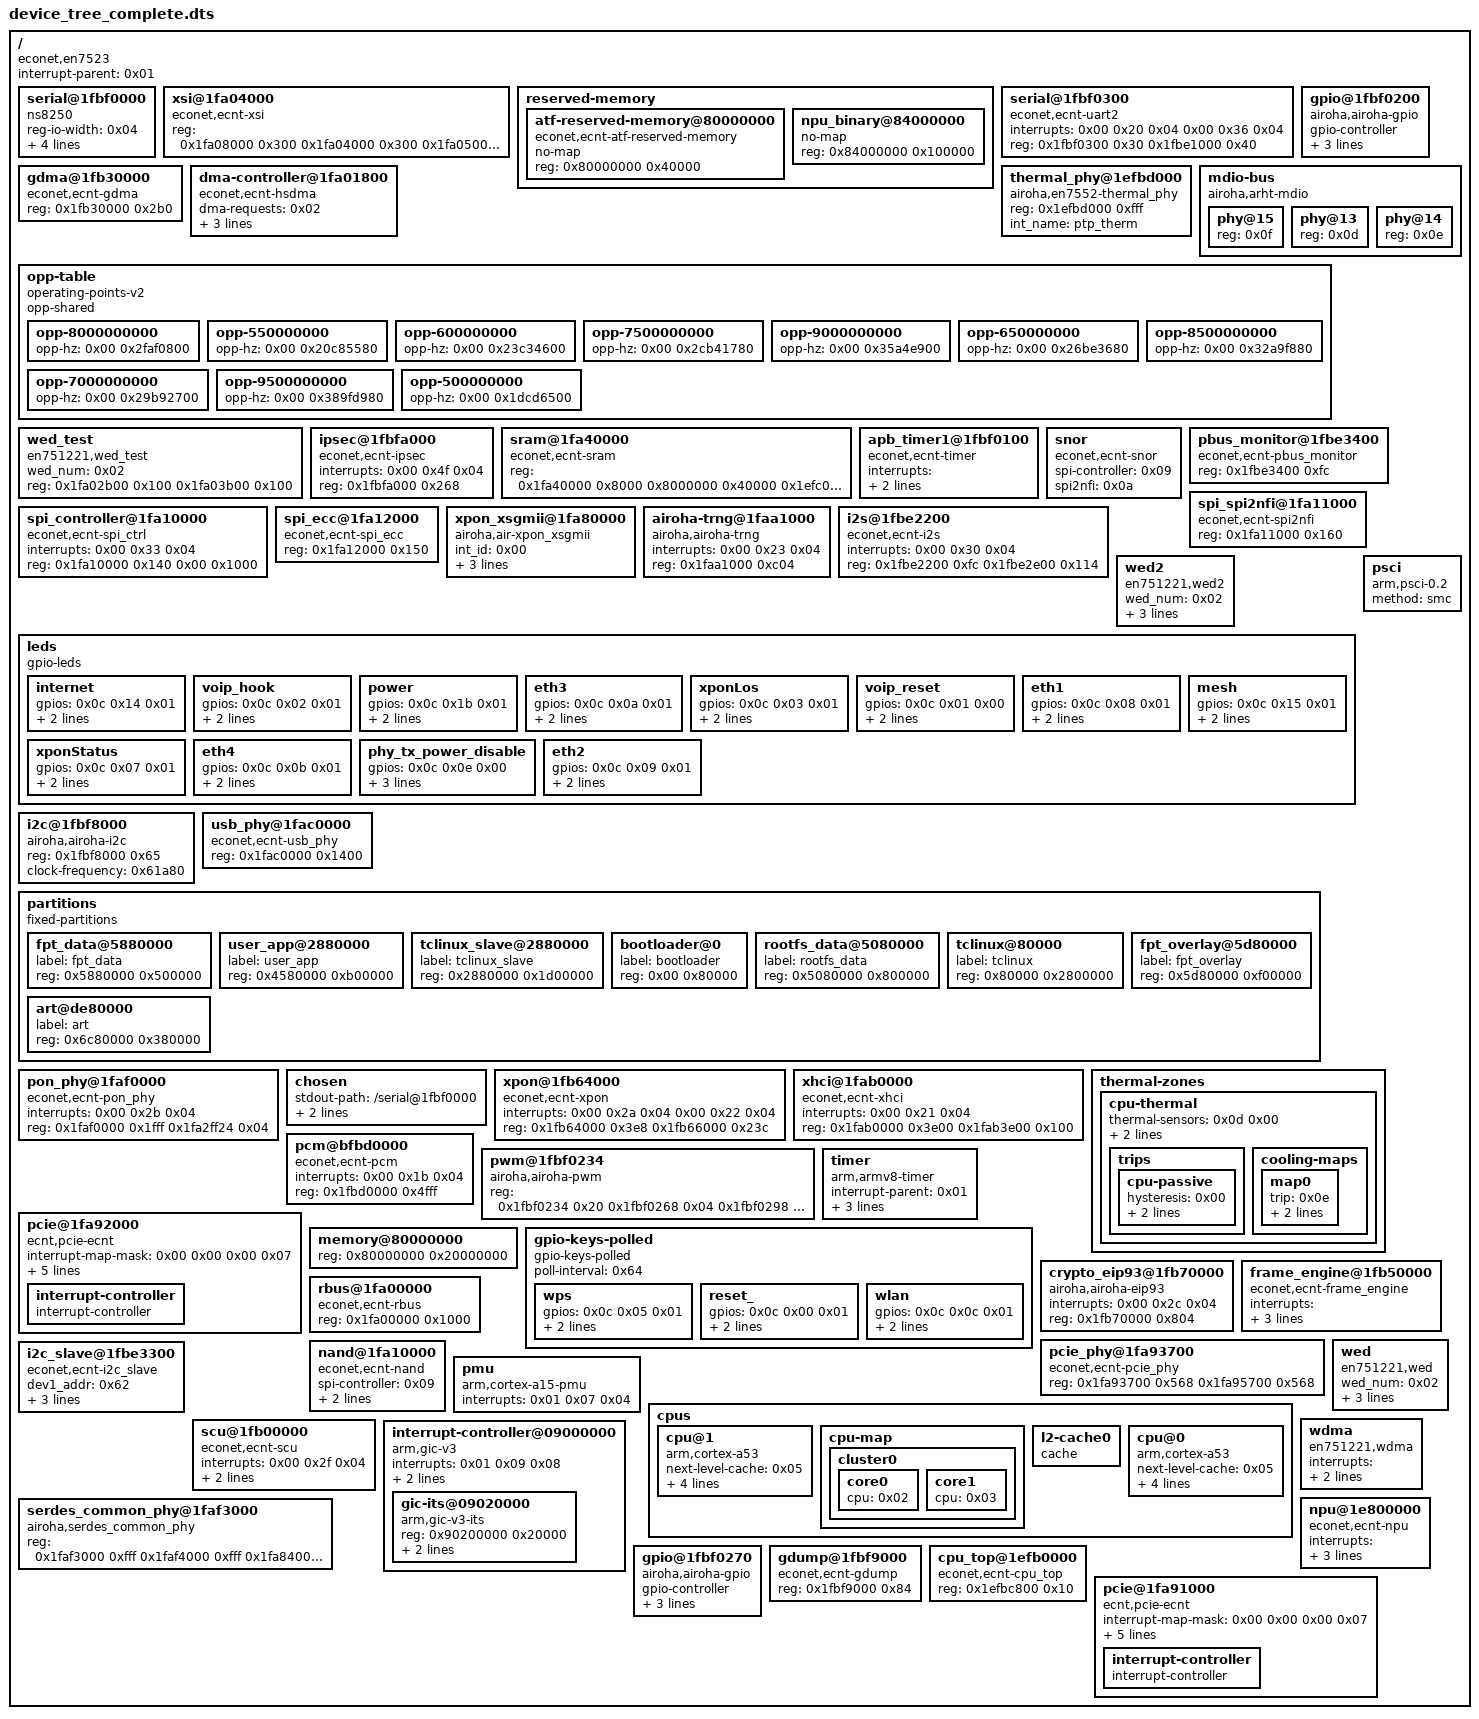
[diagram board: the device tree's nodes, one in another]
/dts-v1/;

/ {
	compatible = "econet,en7523\0airoha,en7523";
	interrupt-parent = <0x01>;
	#address-cells = <0x01>;
	#size-cells = <0x01>;

	serial@1fbf0000 {
		reg-io-width = <0x04>;
		compatible = "ns8250";
		status = "okay";
		interrupts = <0x00 0x12 0x04>;
		reg = <0x1fbf0000 0x30>;
		clock-frequency = <0x1c2000>;
		reg-shift = <0x02>;
	};

	xsi@1fa04000 {
		compatible = "econet,ecnt-xsi";
		reg = <0x1fa08000 0x300 0x1fa04000 0x300 0x1fa05000 0x300 0x1fa07000 0x300 0x1fa09000 0x300>;
	};

	reserved-memory {
		ranges;
		#address-cells = <0x01>;
		#size-cells = <0x01>;

		atf-reserved-memory@80000000 {
			compatible = "econet,ecnt-atf-reserved-memory";
			no-map;
			reg = <0x80000000 0x40000>;
		};

		npu_binary@84000000 {
			no-map;
			phandle = <0x06>;
			reg = <0x84000000 0x100000>;
		};
	};

	serial@1fbf0300 {
		compatible = "econet,ecnt-uart2";
		interrupts = <0x00 0x20 0x04 0x00 0x36 0x04>;
		reg = <0x1fbf0300 0x30 0x1fbe1000 0x40>;
	};

	gdma@1fb30000 {
		compatible = "econet,ecnt-gdma";
		reg = <0x1fb30000 0x2b0>;
	};

	dma-controller@1fa01800 {
		#dma-cells = <0x01>;
		compatible = "econet,ecnt-hsdma";
		dma-requests = <0x02>;
		dma-channels = <0x02>;
		interrupts = <0x00 0x3f 0x04>;
		reg = <0x1fa01800 0x300>;
	};

	thermal_phy@1efbd000 {
		compatible = "airoha,en7552-thermal_phy";
		#thermal-sensor-cells = <0x00>;
		phandle = <0x0d>;
		reg = <0x1efbd000 0xfff>;
		int_name = "ptp_therm";
	};

	gpio@1fbf0200 {
		compatible = "airoha,airoha-gpio";
		gpio-controller;
		phandle = <0x0c>;
		reg = <0x1fbf0204 0x04 0x1fbf0200 0x04 0x1fbf0220 0x04 0x1fbf0214 0x04>;
		#gpio-cells = <0x02>;
		gpio_base = <0x00>;
	};

	mdio-bus {
		compatible = "airoha,arht-mdio";

		phy@15 {
			reg = <0x0f>;
		};

		phy@13 {
			reg = <0x0d>;
		};

		phy@14 {
			reg = <0x0e>;
		};
	};

	opp-table {
		compatible = "operating-points-v2";
		phandle = <0x04>;
		opp-shared;

		opp-8000000000 {
			opp-hz = <0x00 0x2faf0800>;
		};

		opp-550000000 {
			opp-hz = <0x00 0x20c85580>;
		};

		opp-600000000 {
			opp-hz = <0x00 0x23c34600>;
		};

		opp-7500000000 {
			opp-hz = <0x00 0x2cb41780>;
		};

		opp-9000000000 {
			opp-hz = <0x00 0x35a4e900>;
		};

		opp-650000000 {
			opp-hz = <0x00 0x26be3680>;
		};

		opp-8500000000 {
			opp-hz = <0x00 0x32a9f880>;
		};

		opp-7000000000 {
			opp-hz = <0x00 0x29b92700>;
		};

		opp-9500000000 {
			opp-hz = <0x00 0x389fd980>;
		};

		opp-500000000 {
			opp-hz = <0x00 0x1dcd6500>;
		};
	};

	wed_test {
		compatible = "en751221,wed_test";
		wed_num = <0x02>;
		reg = <0x1fa02b00 0x100 0x1fa03b00 0x100>;
	};

	ipsec@1fbfa000 {
		compatible = "econet,ecnt-ipsec";
		interrupts = <0x00 0x4f 0x04>;
		reg = <0x1fbfa000 0x268>;
	};

	sram@1fa40000 {
		compatible = "econet,ecnt-sram";
		reg = <0x1fa40000 0x8000 0x8000000 0x40000 0x1efc0000 0x40000 0x1e880000 0x40000 0x1fbe3000 0x200>;
	};

	apb_timer1@1fbf0100 {
		compatible = "econet,ecnt-timer";
		interrupts = <0x00 0x14 0x04 0x00 0x15 0x04 0x00 0x16 0x04 0x00 0x19 0x04>;
		reg = <0x1fbf0100 0x40>;
	};

	snor {
		compatible = "econet,ecnt-snor";
		spi-controller = <0x09>;
		spi2nfi = <0x0a>;
	};

	pbus_monitor@1fbe3400 {
		compatible = "econet,ecnt-pbus_monitor";
		reg = <0x1fbe3400 0xfc>;
	};

	spi_spi2nfi@1fa11000 {
		compatible = "econet,ecnt-spi2nfi";
		phandle = <0x0a>;
		reg = <0x1fa11000 0x160>;
	};

	spi_controller@1fa10000 {
		compatible = "econet,ecnt-spi_ctrl";
		interrupts = <0x00 0x33 0x04>;
		phandle = <0x09>;
		reg = <0x1fa10000 0x140 0x00 0x1000>;
	};

	spi_ecc@1fa12000 {
		compatible = "econet,ecnt-spi_ecc";
		phandle = <0x0b>;
		reg = <0x1fa12000 0x150>;
	};

	xpon_xsgmii@1fa80000 {
		int_id = <0x00>;
		compatible = "airoha,air-xpon_xsgmii";
		reg = <0x1fa80a00 0x168 0x1fa80000 0x64 0x1fa86000 0x3ff>;
		int_name = "xpon_xsgmii";
	};

	airoha-trng@1faa1000 {
		compatible = "airoha,airoha-trng";
		interrupts = <0x00 0x23 0x04>;
		reg = <0x1faa1000 0xc04>;
	};

	i2s@1fbe2200 {
		compatible = "econet,ecnt-i2s";
		interrupts = <0x00 0x30 0x04>;
		reg = <0x1fbe2200 0xfc 0x1fbe2e00 0x114>;
	};

	wed2 {
		compatible = "en751221,wed2";
		wed_num = <0x02>;
		interrupts = <0x00 0x43 0x04 0x00 0x44 0x04>;
		reg = <0x1fa02000 0xb00 0x1fa03000 0xb00>;
		pci_slot_map = <0x00 0x01>;
	};

	leds {
		compatible = "gpio-leds";

		internet {
			gpios = <0x0c 0x14 0x01>;
			label = "internet";
			linux,default-trigger = "timer";
		};

		voip_hook {
			gpios = <0x0c 0x02 0x01>;
			label = "voip_hook";
			linux,default-trigger = "timer";
		};

		power {
			gpios = <0x0c 0x1b 0x01>;
			label = "power";
			linux,default-trigger = "timer";
		};

		eth3 {
			gpios = <0x0c 0x0a 0x01>;
			label = "eth3";
			linux,default-trigger = "none";
		};

		xponLos {
			gpios = <0x0c 0x03 0x01>;
			label = "xponLos";
			linux,default-trigger = "timer";
		};

		voip_reset {
			gpios = <0x0c 0x01 0x00>;
			label = "voip_reset";
			linux,default-trigger = "none";
		};

		eth1 {
			gpios = <0x0c 0x08 0x01>;
			label = "eth1";
			linux,default-trigger = "none";
		};

		mesh {
			gpios = <0x0c 0x15 0x01>;
			label = "mesh";
			linux,default-trigger = "timer";
		};

		xponStatus {
			gpios = <0x0c 0x07 0x01>;
			label = "xponStatus";
			linux,default-trigger = "timer";
		};

		eth4 {
			gpios = <0x0c 0x0b 0x01>;
			label = "eth4";
			linux,default-trigger = "none";
		};

		phy_tx_power_disable {
			gpios = <0x0c 0x0e 0x00>;
			label = "phy_tx_power_disable";
			default-state = "on";
			linux,default-trigger = "dsldev";
		};

		eth2 {
			gpios = <0x0c 0x09 0x01>;
			label = "eth2";
			linux,default-trigger = "none";
		};
	};

	i2c@1fbf8000 {
		compatible = "airoha,airoha-i2c";
		reg = <0x1fbf8000 0x65>;
		clock-frequency = <0x61a80>;
	};

	psci {
		compatible = "arm,psci-0.2";
		method = "smc";
	};

	usb_phy@1fac0000 {
		compatible = "econet,ecnt-usb_phy";
		reg = <0x1fac0000 0x1400>;
	};

	partitions {
		compatible = "fixed-partitions";
		#address-cells = <0x01>;
		#size-cells = <0x01>;

		fpt_data@5880000 {
			label = "fpt_data";
			reg = <0x5880000 0x500000>;
		};

		user_app@2880000 {
			label = "user_app";
			reg = <0x4580000 0xb00000>;
		};

		tclinux_slave@2880000 {
			label = "tclinux_slave";
			reg = <0x2880000 0x1d00000>;
		};

		bootloader@0 {
			label = "bootloader";
			reg = <0x00 0x80000>;
		};

		rootfs_data@5080000 {
			label = "rootfs_data";
			reg = <0x5080000 0x800000>;
		};

		tclinux@80000 {
			label = "tclinux";
			reg = <0x80000 0x2800000>;
		};

		fpt_overlay@5d80000 {
			label = "fpt_overlay";
			reg = <0x5d80000 0xf00000>;
		};

		art@de80000 {
			label = "art";
			reg = <0x6c80000 0x380000>;
		};
	};

	pon_phy@1faf0000 {
		compatible = "econet,ecnt-pon_phy";
		interrupts = <0x00 0x2b 0x04>;
		reg = <0x1faf0000 0x1fff 0x1fa2ff24 0x04>;
	};

	chosen {
		stdout-path = "/serial@1fbf0000";
		bootargs = "sdram_conf=0x00108893 vendor_name=ECONET Technologies Corp. product_name=xPON ONU ethaddr=20:be:b4:20:b9:b6 snmp_sysobjid=1.2.3.4.5 country_code=ff ether_gpio=0c power_gpio=1b1b dsl_gpio=0b internet_gpio=02 multi_upgrade_gpio=0b020400000000000000000000000000 onu_type=2 qdma_init=33 root=/dev/mtdblock6 ro console=ttyS0,115200n8 earlycon bootflag=1 serdes_sel=0 serdes_sel=0 tclinux_info=0x15876df,0x4cd0,0x3443d0,0x349198,0x1240000,0x1855497,0x4d60,0x3520f8,0x356f50,0x1500000 ";
	};

	xpon@1fb64000 {
		compatible = "econet,ecnt-xpon";
		interrupts = <0x00 0x2a 0x04 0x00 0x22 0x04>;
		reg = <0x1fb64000 0x3e8 0x1fb66000 0x23c>;
	};

	xhci@1fab0000 {
		compatible = "econet,ecnt-xhci";
		interrupts = <0x00 0x21 0x04>;
		reg = <0x1fab0000 0x3e00 0x1fab3e00 0x100>;
	};

	thermal-zones {

		cpu-thermal {
			thermal-sensors = <0x0d 0x00>;
			polling-delay = <0x3e8>;
			polling-delay-passive = <0xc8>;

			trips {

				cpu-passive {
					hysteresis = <0x00>;
					temperature = <0x1e848>;
					type = "passive";
					phandle = <0x0e>;
				};
			};

			cooling-maps {

				map0 {
					trip = <0x0e>;
					cooling-device = <0x02 0xffffffff 0xffffffff 0x03 0xffffffff 0xffffffff>;
				};
			};
		};
	};

	pcm@bfbd0000 {
		compatible = "econet,ecnt-pcm";
		interrupts = <0x00 0x1b 0x04>;
		reg = <0x1fbd0000 0x4fff>;
	};

	pwm@1fbf0234 {
		compatible = "airoha,airoha-pwm";
		reg = <0x1fbf0234 0x20 0x1fbf0268 0x04 0x1fbf0298 0x24>;
	};

	pcie@1fa92000 {
		compatible = "ecnt,pcie-ecnt";
		reg-names = "pcie-mac";
		device_type = "pci";
		interrupt-map-mask = <0x00 0x00 0x00 0x07>;
		ranges = <0x82000000 0x00 0x24000000 0x24000000 0x00 0x4000000>;
		#interrupt-cells = <0x01>;
		bus-range = <0x00 0xff>;
		#address-cells = <0x03>;
		interrupts = <0x00 0x28 0x04>;
		interrupt-map = <0x00 0x00 0x00 0x01 0x08 0x01 0x00 0x00 0x00 0x02 0x08 0x02 0x00 0x00 0x00 0x03 0x08 0x03 0x00 0x00 0x00 0x04 0x08 0x04>;
		reg = <0x1fa92000 0x1000>;

		interrupt-controller {
			#interrupt-cells = <0x01>;
			#address-cells = <0x00>;
			phandle = <0x08>;
			interrupt-controller;
		};
	};

	timer {
		compatible = "arm,armv8-timer";
		interrupt-parent = <0x01>;
		interrupts = <0x01 0x0d 0xf08 0x01 0x0e 0xf08 0x01 0x0b 0xf08 0x01 0x0a 0xf08>;
		clock-frequency = <0x17d7840>;
	};

	memory@80000000 {
		device_type = "memory";
		reg = <0x80000000 0x20000000>;
	};

	gpio-keys-polled {
		compatible = "gpio-keys-polled";
		poll-interval = <0x64>;

		wps {
			gpios = <0x0c 0x05 0x01>;
			label = "wps";
			linux,code = <0x211>;
		};

		reset_ {
			gpios = <0x0c 0x00 0x01>;
			label = "reset_";
			linux,code = <0x100>;
		};

		wlan {
			gpios = <0x0c 0x0c 0x01>;
			label = "wlan";
			linux,code = <0xee>;
		};
	};

	crypto_eip93@1fb70000 {
		compatible = "airoha,airoha-eip93";
		interrupts = <0x00 0x2c 0x04>;
		reg = <0x1fb70000 0x804>;
	};

	frame_engine@1fb50000 {
		compatible = "econet,ecnt-frame_engine";
		interrupts = <0x00 0x25 0x04 0x00 0x37 0x04 0x00 0x38 0x04 0x00 0x39 0x04 0x00 0x26 0x04 0x00 0x3a 0x04 0x00 0x3b 0x04 0x00 0x3c 0x04 0x00 0x31 0x04 0x00 0x40 0x04>;
		reg = <0x1fb50000 0x2600 0x1fb54000 0x4000 0x1fb58000 0x8000>;
	};

	rbus@1fa00000 {
		compatible = "econet,ecnt-rbus";
		reg = <0x1fa00000 0x1000>;
	};

	pcie_phy@1fa93700 {
		compatible = "econet,ecnt-pcie_phy";
		reg = <0x1fa93700 0x568 0x1fa95700 0x568>;
	};

	nand@1fa10000 {
		compatible = "econet,ecnt-nand";
		spi-controller = <0x09>;
		spi2nfi = <0x0a>;
		spi-ecc = <0x0b>;
	};

	i2c_slave@1fbe3300 {
		compatible = "econet,ecnt-i2c_slave";
		dev1_addr = <0x62>;
		dev0_addr = <0x60>;
		interrupts = <0x00 0x1c 0x04>;
		reg = <0x1fbe3300 0x10>;
	};

	pmu {
		compatible = "arm,cortex-a15-pmu";
		interrupts = <0x01 0x07 0x04>;
	};

	wed {
		compatible = "en751221,wed";
		wed_num = <0x02>;
		interrupts = <0x00 0x43 0x04 0x00 0x43 0x04>;
		reg = <0x1fa02000 0xb00 0x1fa02000 0xb00>;
		pci_slot_map = <0x00 0x01>;
	};

	cpus {
		#address-cells = <0x01>;
		#size-cells = <0x00>;

		cpu@1 {
			compatible = "arm,cortex-a53";
			device_type = "cpu";
			next-level-cache = <0x05>;
			enable-method = "psci";
			phandle = <0x03>;
			operating-points-v2 = <0x04>;
			reg = <0x01>;
			clock-frequency = <0x4c4b400>;
			#cooling-cells = <0x02>;
		};

		cpu-map {

			cluster0 {

				core0 {
					cpu = <0x02>;
				};

				core1 {
					cpu = <0x03>;
				};
			};
		};

		l2-cache0 {
			compatible = "cache";
			phandle = <0x05>;
		};

		cpu@0 {
			compatible = "arm,cortex-a53";
			device_type = "cpu";
			next-level-cache = <0x05>;
			enable-method = "psci";
			phandle = <0x02>;
			operating-points-v2 = <0x04>;
			reg = <0x00>;
			clock-frequency = <0x4c4b400>;
			#cooling-cells = <0x02>;
		};
	};

	wdma {
		compatible = "en751221,wdma";
		interrupts = <0x00 0x45 0x04 0x00 0x46 0x04 0x00 0x47 0x04 0x00 0x48 0x04 0x00 0x49 0x04 0x00 0x4a 0x04>;
		reg = <0x1fa06000 0x400 0x1fa06400 0x400>;
	};

	scu@1fb00000 {
		compatible = "econet,ecnt-scu";
		interrupts = <0x00 0x2f 0x04>;
		reg = <0x1fb00000 0x960 0x1fa20000 0x360 0x1fa2ff30 0x10>;
	};

	interrupt-controller@09000000 {
		compatible = "arm,gic-v3";
		#interrupt-cells = <0x03>;
		#address-cells = <0x01>;
		interrupts = <0x01 0x09 0x08>;
		#size-cells = <0x01>;
		phandle = <0x01>;
		reg = <0x9000000 0x20000 0x9080000 0x80000>;
		interrupt-controller;

		gic-its@09020000 {
			compatible = "arm,gic-v3-its";
			reg = <0x90200000 0x20000>;
			#msi-cell = <0x01>;
			msi-controller;
		};
	};

	serdes_common_phy@1faf3000 {
		compatible = "airoha,serdes_common_phy";
		reg = <0x1faf3000 0xfff 0x1faf4000 0xfff 0x1fa84000 0x685>;
	};

	npu@1e800000 {
		compatible = "econet,ecnt-npu";
		interrupts = <0x00 0x76 0x04 0x00 0x77 0x04 0x00 0x78 0x04 0x00 0x79 0x04 0x00 0x7a 0x04 0x00 0x7b 0x04 0x00 0x7d 0x04 0x00 0x86 0x04 0x00 0x87 0x04>;
		memory-region = <0x06>;
		reg = <0x1e800000 0x60000 0x1e900000 0x313000>;
	};

	gpio@1fbf0270 {
		compatible = "airoha,airoha-gpio";
		gpio-controller;
		reg = <0x1fbf0270 0x04 0x1fbf0260 0x04 0x1fbf0264 0x04 0x1fbf0278 0x04>;
		#gpio-cells = <0x02>;
		gpio_base = <0x20>;
	};

	gdump@1fbf9000 {
		compatible = "econet,ecnt-gdump";
		reg = <0x1fbf9000 0x84>;
	};

	cpu_top@1efb0000 {
		compatible = "econet,ecnt-cpu_top";
		reg = <0x1efbc800 0x10>;
	};

	pcie@1fa91000 {
		compatible = "ecnt,pcie-ecnt";
		reg-names = "pcie-mac";
		device_type = "pci";
		interrupt-map-mask = <0x00 0x00 0x00 0x07>;
		ranges = <0x82000000 0x00 0x20000000 0x20000000 0x00 0x4000000>;
		#interrupt-cells = <0x01>;
		bus-range = <0x00 0xff>;
		#address-cells = <0x03>;
		interrupts = <0x00 0x27 0x04>;
		interrupt-map = <0x00 0x00 0x00 0x01 0x07 0x01 0x00 0x00 0x00 0x02 0x07 0x02 0x00 0x00 0x00 0x03 0x07 0x03 0x00 0x00 0x00 0x04 0x07 0x04>;
		#size-cells = <0x02>;
		reg = <0x1fa91000 0x1000>;

		interrupt-controller {
			#interrupt-cells = <0x01>;
			#address-cells = <0x00>;
			phandle = <0x07>;
			interrupt-controller;
		};
	};
};
